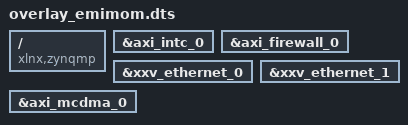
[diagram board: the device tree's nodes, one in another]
// SPDX-License-Identifier: GPL-2.0-or-later OR MIT
/*
 * Copyright 2022 xi.he@zillnk.com
 */

/dts-v1/;
/plugin/;

/ {
	compatible = "xlnx,zynqmp";
};


&axi_intc_0 {
    status = "okay";
};

&axi_firewall_0 {
    status = "okay";
};

&xxv_ethernet_0 {
	status = "okay";
};

&xxv_ethernet_1 {
	status = "okay";
};

&axi_mcdma_0 {
	status = "okay";
};

